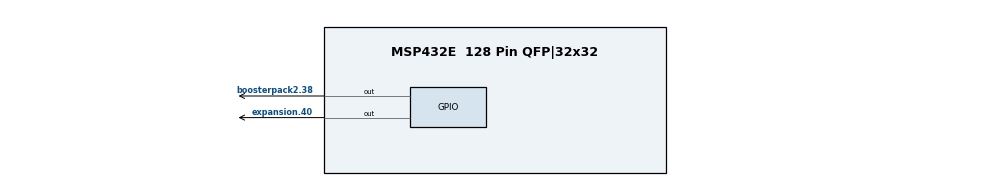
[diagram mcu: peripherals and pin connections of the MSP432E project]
/**
 * @cliArgs --board "/ti/boards/MSP_EXP432E401Y" --device "MSP432E" --part "MSP432E401YTPDT" --package "128 Pin QFP|32x32" --product "simplelink_msp432e4_sdk@4.20.00.12"
 * @versions {"tool":"1.21.0+3721"}
 */

/**
 * Import the modules used in this configuration.
 */
const GPIO  = scripting.addModule("/ti/drivers/GPIO");
const GPIO1 = GPIO.addInstance();
const GPIO2 = GPIO.addInstance();
const GPIO3 = GPIO.addInstance();
const GPIO4 = GPIO.addInstance();
const GPIO5 = GPIO.addInstance();
const GPIO6 = GPIO.addInstance();
const GPIO7 = GPIO.addInstance();
const GPIO8 = GPIO.addInstance();
const RTOS  = scripting.addModule("/ti/drivers/RTOS");
const UART  = scripting.addModule("/ti/drivers/UART");
const UART1 = UART.addInstance();
const UART2 = UART.addInstance();

/**
 * Write custom configuration values to the imported modules.
 */
GPIO1.$hardware = system.deviceData.board.components.D1;
GPIO1.$name     = "CONFIG_GPIO_LED0";

GPIO2.$hardware = system.deviceData.board.components.D2;
GPIO2.$name     = "CONFIG_GPIO_LED1";

GPIO3.$hardware = system.deviceData.board.components.D3;
GPIO3.$name     = "CONFIG_GPIO_LED2";

GPIO4.$hardware = system.deviceData.board.components.D4;
GPIO4.$name     = "CONFIG_GPIO_LED3";

GPIO5.mode            = "Output";
GPIO5.$name           = "CONFIG_GPIO_AUDIO_PWR";
GPIO5.gpioPin.$assign = "boosterpack2.38";

GPIO6.mode            = "Output";
GPIO6.$name           = "CONFIG_GPIO_MIC_PWR";
GPIO6.gpioPin.$assign = "expansion.40";

GPIO7.$hardware = system.deviceData.board.components.USR_SW1;
GPIO7.$name     = "CONFIG_GPIO_SW1";

GPIO8.$hardware = system.deviceData.board.components.USR_SW2;
GPIO8.$name     = "CONFIG_GPIO_SW2";


UART1.$name             = "CONFIG_UART_0";
UART1.$hardware         = system.deviceData.board.components.XDS110UART;
UART1.interruptPriority = "4";

UART2.$name = "CONFIG_UART_1";

/**
 * These are the reserved peripherals and settings in this configuration
 */
const iSHA1 = scripting.addPeripheral("SHA");
iSHA1.$name = "MySHA1";

/**
 * Pinmux solution for unlocked pins/peripherals. This ensures that minor changes to the automatic solver in a future
 * version of the tool will not impact the pinmux you originally saw.  These lines can be completely deleted in order to
 * re-solve from scratch.
 */
GPIO1.gpioPin.$suggestSolution        = "expansion.87";
GPIO2.gpioPin.$suggestSolution        = "expansion.85";
GPIO3.gpioPin.$suggestSolution        = "expansion.64";
GPIO4.gpioPin.$suggestSolution        = "expansion.66";
GPIO7.gpioPin.$suggestSolution        = "expansion.82";
GPIO8.gpioPin.$suggestSolution        = "expansion.84";
RTOS.timer0.resource.$suggestSolution = "Timer0";
UART1.uart.$suggestSolution           = "UART0";
UART1.uart.txPin.$suggestSolution     = "expansion.76";
UART1.uart.rxPin.$suggestSolution     = "expansion.74";
UART2.uart.$suggestSolution           = "UART6";
UART2.uart.txPin.$suggestSolution     = "boosterpack2.4";
UART2.uart.rxPin.$suggestSolution     = "boosterpack2.3";
iSHA1.$suggestSolution                = "SHA0";
iSHA1.DMA_MD5.$suggestSolution        = "UDMA_CH4";
